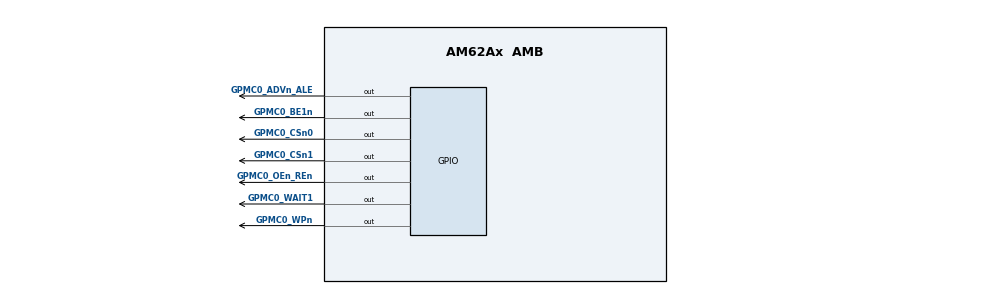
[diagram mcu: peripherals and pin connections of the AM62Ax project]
/**
 * @cliArgs --device "AM62Ax" --part "Default" --package "AMB" --context "c75ss0-0" --product "MCU_PLUS_SDK@07.03.01"
 * @versions {"tool":"1.26.2+4477"}
 */

/**
 * Import the modules used in this configuration.
 */
const eqep        = scripting.addModule("/drivers/eqep/eqep", {}, false);
const eqep1       = eqep.addInstance();
const eqep2       = eqep.addInstance();
const eqep3       = eqep.addInstance();
const gpio        = scripting.addModule("/drivers/gpio/gpio", {}, false);
const gpio1       = gpio.addInstance();
const gpio2       = gpio.addInstance();
const gpio3       = gpio.addInstance();
const gpio4       = gpio.addInstance();
const gpio5       = gpio.addInstance();
const gpio6       = gpio.addInstance();
const gpio7       = gpio.addInstance();
const i2c         = scripting.addModule("/drivers/i2c/i2c", {}, false);
const i2c1        = i2c.addInstance();
const ipc         = scripting.addModule("/drivers/ipc/ipc");
const debug_log   = scripting.addModule("/kernel/dpl/debug_log");
const mmu_armv8   = scripting.addModule("/kernel/dpl/mmu_armv8", {}, false);
const mmu_armv81  = mmu_armv8.addInstance();
const mmu_armv82  = mmu_armv8.addInstance();
const mmu_armv83  = mmu_armv8.addInstance();
const mmu_armv84  = mmu_armv8.addInstance();
const mmu_armv85  = mmu_armv8.addInstance();
const mmu_armv86  = mmu_armv8.addInstance();
const mmu_armv87  = mmu_armv8.addInstance();
const mmu_armv88  = mmu_armv8.addInstance();
const mmu_armv89  = mmu_armv8.addInstance();
const mmu_armv810 = mmu_armv8.addInstance();
const mmu_armv811 = mmu_armv8.addInstance();
const mmu_armv812 = mmu_armv8.addInstance();
const mmu_armv813 = mmu_armv8.addInstance();

/**
 * Write custom configuration values to the imported modules.
 */
eqep1.$name          = "CONFIG_EQEP0";
eqep1.EQEP.$assign   = "EQEP2";
eqep1.EQEP.A.$assign = "I2C0_SCL";
eqep1.EQEP.B.$assign = "I2C0_SDA";
eqep1.EQEP.I.$assign = "MCAN0_TX";
eqep1.EQEP.S.$assign = "MCAN0_RX";

eqep2.$name          = "CONFIG_EQEP1";
eqep2.EQEP.$assign   = "EQEP1";
eqep2.EQEP.A.$assign = "MCASP0_ACLKX";
eqep2.EQEP.B.$assign = "MCASP0_AFSX";
eqep2.EQEP.I.$assign = "MCASP0_ACLKR";
eqep2.EQEP.S.$assign = "MCASP0_AFSR";

eqep3.$name          = "CONFIG_EQEP2";
eqep3.EQEP.$assign   = "EQEP0";
eqep3.EQEP.A.$assign = "MCASP0_AXR3";
eqep3.EQEP.B.$assign = "MCASP0_AXR2";
eqep3.EQEP.I.$assign = "MCASP0_AXR0";
eqep3.EQEP.S.$assign = "MCASP0_AXR1";

gpio1.$name                = "CONFIG_GPIO0";
gpio1.pinDir               = "OUTPUT";
gpio1.GPIO.gpioPin.rx      = false;
gpio1.GPIO.gpioPin.$assign = "GPMC0_WAIT1";

gpio2.$name                = "CONFIG_GPIO1";
gpio2.pinDir               = "OUTPUT";
gpio2.GPIO.gpioPin.rx      = false;
gpio2.GPIO.gpioPin.$assign = "GPMC0_WPn";

gpio3.$name                = "CONFIG_GPIO2";
gpio3.pinDir               = "OUTPUT";
gpio3.GPIO.gpioPin.rx      = false;
gpio3.GPIO.gpioPin.$assign = "GPMC0_ADVn_ALE";

gpio4.$name                = "CONFIG_GPIO3";
gpio4.pinDir               = "OUTPUT";
gpio4.GPIO.gpioPin.rx      = false;
gpio4.GPIO.gpioPin.$assign = "GPMC0_OEn_REn";

gpio5.$name                = "CONFIG_GPIO4";
gpio5.pinDir               = "OUTPUT";
gpio5.GPIO.gpioPin.rx      = false;
gpio5.GPIO.gpioPin.$assign = "GPMC0_CSn0";

gpio6.$name                = "CONFIG_GPIO5";
gpio6.pinDir               = "OUTPUT";
gpio6.GPIO.gpioPin.rx      = false;
gpio6.GPIO.gpioPin.$assign = "GPMC0_CSn1";

gpio7.$name                = "CONFIG_GPIO6";
gpio7.pinDir               = "OUTPUT";
gpio7.GPIO.gpioPin.rx      = false;
gpio7.GPIO.gpioPin.$assign = "GPMC0_BE1n";

i2c1.$name           = "CONFIG_I2C0";
i2c1.I2C.$assign     = "I2C1";
i2c1.I2C_child.$name = "drivers_i2c_v0_i2c_v0_template0";

ipc.enableLinuxIpc = false;
ipc.a53ss0_0       = "notify";
ipc.r5fss0_0       = "notify";
ipc.mcu_r5fss0_0   = "NONE";

debug_log.enableSharedMemLog = true;

mmu_armv81.$name = "CONFIG_MMU_REGION0";
mmu_armv81.size  = 0x20000000;

mmu_armv82.$name = "CONFIG_MMU_REGION1";
mmu_armv82.vAddr = 0x20000000;
mmu_armv82.pAddr = 0x20000000;
mmu_armv82.size  = 0x20000000;

mmu_armv83.$name = "CONFIG_MMU_REGION2";
mmu_armv83.vAddr = 0x40000000;
mmu_armv83.pAddr = 0x40000000;
mmu_armv83.size  = 0x20000000;

mmu_armv84.$name = "CONFIG_MMU_REGION3";
mmu_armv84.vAddr = 0x60000000;
mmu_armv84.pAddr = 0x60000000;
mmu_armv84.size  = 0x10000000;

mmu_armv85.vAddr = 0x7C200000;
mmu_armv85.pAddr = 0x7C200000;
mmu_armv85.size  = 0x100000;
mmu_armv85.$name = "CLEC";

mmu_armv86.vAddr = 0x7C400000;
mmu_armv86.pAddr = 0x7C400000;
mmu_armv86.size  = 0x100000;
mmu_armv86.$name = "DRU";

mmu_armv87.vAddr     = 0x80000000;
mmu_armv87.pAddr     = 0x80000000;
mmu_armv87.size      = 0x20000000;
mmu_armv87.$name     = "DDR_0";
mmu_armv87.attribute = "MAIR7";

mmu_armv88.vAddr     = 0xA0000000;
mmu_armv88.pAddr     = 0xA0000000;
mmu_armv88.size      = 0x20000000;
mmu_armv88.attribute = "MAIR7";
mmu_armv88.$name     = "DDR_1";

mmu_armv89.size      = 0x300000;
mmu_armv89.$name     = "VRING";
mmu_armv89.attribute = "MAIR4";
mmu_armv89.vAddr     = 0xA0400000;
mmu_armv89.pAddr     = 0xA0400000;

mmu_armv810.$name     = "CONFIG_MMU_REGION4";
mmu_armv810.vAddr     = 0xAA000000;
mmu_armv810.pAddr     = 0xAA000000;
mmu_armv810.size      = 0x2000000;
mmu_armv810.attribute = "MAIR4";

mmu_armv811.$name     = "CONFIG_MMU_REGION5";
mmu_armv811.vAddr     = 0x99800000;
mmu_armv811.pAddr     = 0x99800000;
mmu_armv811.size      = 0x1000000;
mmu_armv811.attribute = "MAIR4";

mmu_armv812.$name     = "LOG_SHM_MEM";
mmu_armv812.vAddr     = 0xA1000000;
mmu_armv812.pAddr     = 0xA1000000;
mmu_armv812.size      = 0x40000;
mmu_armv812.attribute = "MAIR4";

mmu_armv813.$name     = "CCS_DEBUG_LOG_MEM";
mmu_armv813.vAddr     = 0x99C10000;
mmu_armv813.pAddr     = 0x99C10000;
mmu_armv813.size      = 0x1000;
mmu_armv813.attribute = "MAIR4";

/**
 * Pinmux solution for unlocked pins/peripherals. This ensures that minor changes to the automatic solver in a future
 * version of the tool will not impact the pinmux you originally saw.  These lines can be completely deleted in order to
 * re-solve from scratch.
 */
gpio1.GPIO.$suggestSolution   = "GPIO0";
gpio2.GPIO.$suggestSolution   = "GPIO0";
gpio3.GPIO.$suggestSolution   = "GPIO0";
gpio4.GPIO.$suggestSolution   = "GPIO0";
gpio5.GPIO.$suggestSolution   = "GPIO0";
gpio6.GPIO.$suggestSolution   = "GPIO0";
gpio7.GPIO.$suggestSolution   = "GPIO0";
i2c1.I2C.SCL.$suggestSolution = "I2C1_SCL";
i2c1.I2C.SDA.$suggestSolution = "I2C1_SDA";
